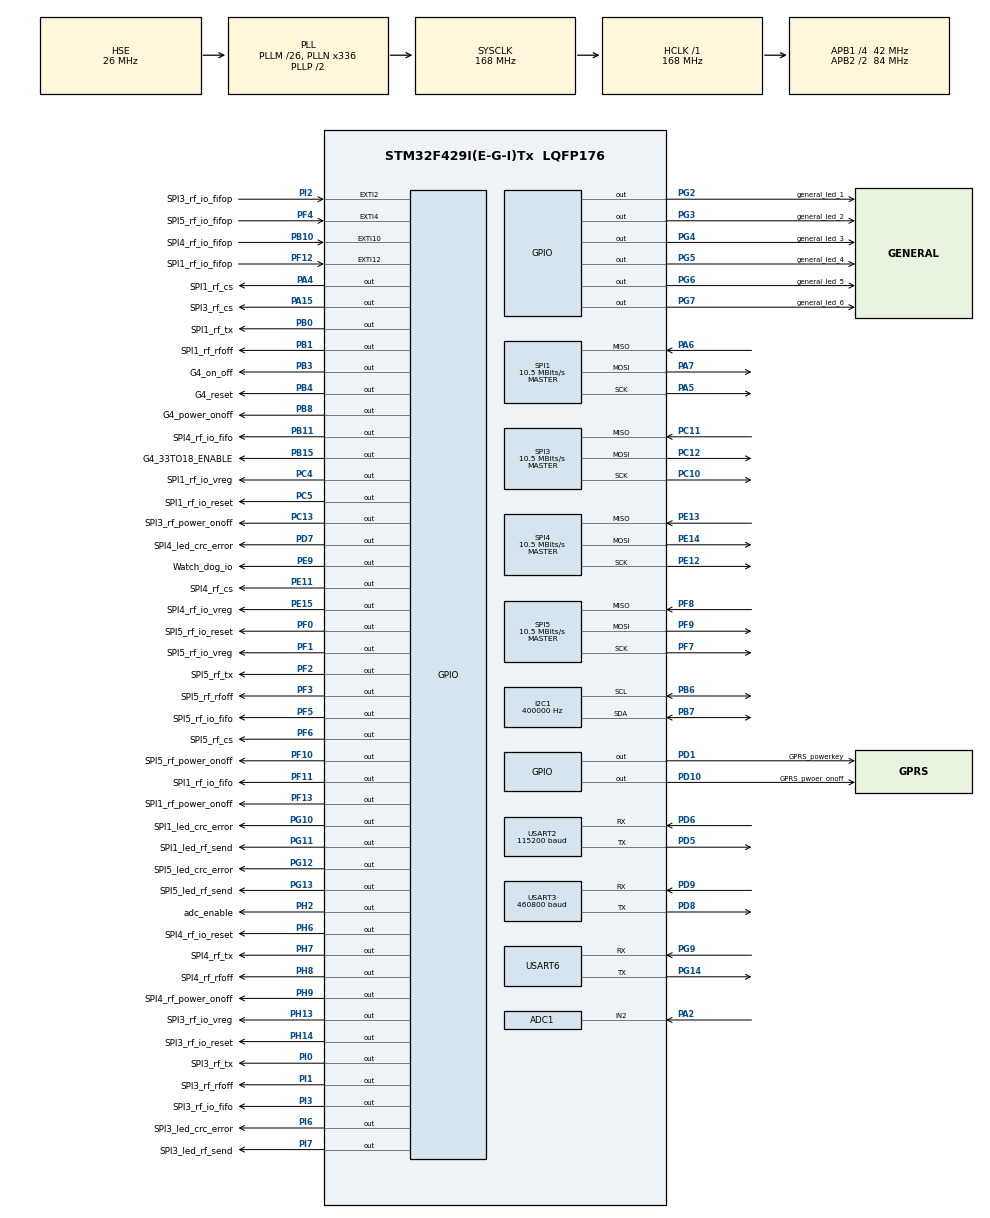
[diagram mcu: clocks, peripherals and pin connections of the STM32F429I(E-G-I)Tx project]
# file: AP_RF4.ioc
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ADC1.Channel-0\#ChannelRegularConversion=ADC_CHANNEL_2
ADC1.Channel-1\#ChannelRegularConversion=ADC_CHANNEL_2
ADC1.Channel-2\#ChannelRegularConversion=ADC_CHANNEL_2
ADC1.Channel-3\#ChannelRegularConversion=ADC_CHANNEL_2
ADC1.Channel-4\#ChannelRegularConversion=ADC_CHANNEL_2
ADC1.Channel-5\#ChannelRegularConversion=ADC_CHANNEL_2
ADC1.Channel-6\#ChannelRegularConversion=ADC_CHANNEL_2
ADC1.Channel-7\#ChannelRegularConversion=ADC_CHANNEL_2
ADC1.Channel-8\#ChannelRegularConversion=ADC_CHANNEL_2
ADC1.Channel-9\#ChannelRegularConversion=ADC_CHANNEL_2
ADC1.InjNumberOfConversion=0
ADC1.NbrOfConversion=10
ADC1.NbrOfConversionFlag=1
ADC1.Rank-0\#ChannelRegularConversion=1
ADC1.Rank-1\#ChannelRegularConversion=2
ADC1.Rank-2\#ChannelRegularConversion=3
ADC1.Rank-3\#ChannelRegularConversion=4
ADC1.Rank-4\#ChannelRegularConversion=5
ADC1.Rank-5\#ChannelRegularConversion=6
ADC1.Rank-6\#ChannelRegularConversion=7
ADC1.Rank-7\#ChannelRegularConversion=8
ADC1.Rank-8\#ChannelRegularConversion=9
ADC1.Rank-9\#ChannelRegularConversion=10
ADC1.SamplingTime-0\#ChannelRegularConversion=ADC_SAMPLETIME_3CYCLES
ADC1.SamplingTime-1\#ChannelRegularConversion=ADC_SAMPLETIME_3CYCLES
ADC1.SamplingTime-2\#ChannelRegularConversion=ADC_SAMPLETIME_3CYCLES
ADC1.SamplingTime-3\#ChannelRegularConversion=ADC_SAMPLETIME_3CYCLES
ADC1.SamplingTime-4\#ChannelRegularConversion=ADC_SAMPLETIME_3CYCLES
ADC1.SamplingTime-5\#ChannelRegularConversion=ADC_SAMPLETIME_3CYCLES
ADC1.SamplingTime-6\#ChannelRegularConversion=ADC_SAMPLETIME_3CYCLES
ADC1.SamplingTime-7\#ChannelRegularConversion=ADC_SAMPLETIME_3CYCLES
ADC1.SamplingTime-8\#ChannelRegularConversion=ADC_SAMPLETIME_3CYCLES
ADC1.SamplingTime-9\#ChannelRegularConversion=ADC_SAMPLETIME_3CYCLES
ADC1.ScanConvMode=ENABLE
ADC1.master=1
Dma.I2C1_RX.6.Direction=DMA_PERIPH_TO_MEMORY
Dma.I2C1_RX.6.FIFOMode=DMA_FIFOMODE_DISABLE
Dma.I2C1_RX.6.Instance=DMA1_Stream0
Dma.I2C1_RX.6.MemDataAlignment=DMA_MDATAALIGN_BYTE
Dma.I2C1_RX.6.MemInc=DMA_MINC_ENABLE
Dma.I2C1_RX.6.Mode=DMA_NORMAL
Dma.I2C1_RX.6.PeriphDataAlignment=DMA_PDATAALIGN_BYTE
Dma.I2C1_RX.6.PeriphInc=DMA_PINC_DISABLE
Dma.I2C1_RX.6.Priority=DMA_PRIORITY_VERY_HIGH
Dma.I2C1_TX.7.Direction=DMA_MEMORY_TO_PERIPH
Dma.I2C1_TX.7.FIFOMode=DMA_FIFOMODE_DISABLE
Dma.I2C1_TX.7.Instance=DMA1_Stream7
Dma.I2C1_TX.7.MemDataAlignment=DMA_MDATAALIGN_BYTE
Dma.I2C1_TX.7.MemInc=DMA_MINC_ENABLE
Dma.I2C1_TX.7.Mode=DMA_NORMAL
Dma.I2C1_TX.7.PeriphDataAlignment=DMA_PDATAALIGN_BYTE
Dma.I2C1_TX.7.PeriphInc=DMA_PINC_DISABLE
Dma.I2C1_TX.7.Priority=DMA_PRIORITY_VERY_HIGH
Dma.Request0=USART2_RX
Dma.Request1=USART2_TX
Dma.Request10=USART3_RX
Dma.Request11=USART3_TX
Dma.Request2=SPI1_RX
Dma.Request3=SPI5_RX
Dma.Request4=SPI4_RX
Dma.Request5=SPI3_RX
Dma.Request6=I2C1_RX
Dma.Request7=I2C1_TX
Dma.Request8=USART6_RX
Dma.Request9=USART6_TX
Dma.SPI1_RX.2.Direction=DMA_PERIPH_TO_MEMORY
Dma.SPI1_RX.2.FIFOMode=DMA_FIFOMODE_DISABLE
Dma.SPI1_RX.2.Instance=DMA2_Stream2
Dma.SPI1_RX.2.MemDataAlignment=DMA_MDATAALIGN_BYTE
Dma.SPI1_RX.2.MemInc=DMA_MINC_ENABLE
Dma.SPI1_RX.2.Mode=DMA_NORMAL
Dma.SPI1_RX.2.PeriphDataAlignment=DMA_PDATAALIGN_BYTE
Dma.SPI1_RX.2.PeriphInc=DMA_PINC_DISABLE
Dma.SPI1_RX.2.Priority=DMA_PRIORITY_MEDIUM
Dma.SPI3_RX.5.Direction=DMA_PERIPH_TO_MEMORY
Dma.SPI3_RX.5.FIFOMode=DMA_FIFOMODE_DISABLE
Dma.SPI3_RX.5.Instance=DMA1_Stream2
Dma.SPI3_RX.5.MemDataAlignment=DMA_MDATAALIGN_BYTE
Dma.SPI3_RX.5.MemInc=DMA_MINC_ENABLE
Dma.SPI3_RX.5.Mode=DMA_NORMAL
Dma.SPI3_RX.5.PeriphDataAlignment=DMA_PDATAALIGN_BYTE
Dma.SPI3_RX.5.PeriphInc=DMA_PINC_DISABLE
Dma.SPI3_RX.5.Priority=DMA_PRIORITY_MEDIUM
Dma.SPI4_RX.4.Direction=DMA_PERIPH_TO_MEMORY
Dma.SPI4_RX.4.FIFOMode=DMA_FIFOMODE_DISABLE
Dma.SPI4_RX.4.Instance=DMA2_Stream0
Dma.SPI4_RX.4.MemDataAlignment=DMA_MDATAALIGN_BYTE
Dma.SPI4_RX.4.MemInc=DMA_MINC_ENABLE
Dma.SPI4_RX.4.Mode=DMA_NORMAL
Dma.SPI4_RX.4.PeriphDataAlignment=DMA_PDATAALIGN_BYTE
Dma.SPI4_RX.4.PeriphInc=DMA_PINC_DISABLE
Dma.SPI4_RX.4.Priority=DMA_PRIORITY_MEDIUM
Dma.SPI5_RX.3.Direction=DMA_PERIPH_TO_MEMORY
Dma.SPI5_RX.3.FIFOMode=DMA_FIFOMODE_DISABLE
Dma.SPI5_RX.3.Instance=DMA2_Stream3
Dma.SPI5_RX.3.MemDataAlignment=DMA_MDATAALIGN_BYTE
Dma.SPI5_RX.3.MemInc=DMA_MINC_ENABLE
Dma.SPI5_RX.3.Mode=DMA_NORMAL
Dma.SPI5_RX.3.PeriphDataAlignment=DMA_PDATAALIGN_BYTE
Dma.SPI5_RX.3.PeriphInc=DMA_PINC_DISABLE
Dma.SPI5_RX.3.Priority=DMA_PRIORITY_MEDIUM
Dma.USART2_RX.0.Direction=DMA_PERIPH_TO_MEMORY
Dma.USART2_RX.0.FIFOMode=DMA_FIFOMODE_DISABLE
Dma.USART2_RX.0.Instance=DMA1_Stream5
Dma.USART2_RX.0.MemDataAlignment=DMA_MDATAALIGN_BYTE
Dma.USART2_RX.0.MemInc=DMA_MINC_ENABLE
Dma.USART2_RX.0.Mode=DMA_NORMAL
Dma.USART2_RX.0.PeriphDataAlignment=DMA_PDATAALIGN_BYTE
Dma.USART2_RX.0.PeriphInc=DMA_PINC_DISABLE
Dma.USART2_RX.0.Priority=DMA_PRIORITY_MEDIUM
Dma.USART2_TX.1.Direction=DMA_MEMORY_TO_PERIPH
Dma.USART2_TX.1.FIFOMode=DMA_FIFOMODE_DISABLE
Dma.USART2_TX.1.Instance=DMA1_Stream6
Dma.USART2_TX.1.MemDataAlignment=DMA_MDATAALIGN_BYTE
Dma.USART2_TX.1.MemInc=DMA_MINC_ENABLE
Dma.USART2_TX.1.Mode=DMA_NORMAL
Dma.USART2_TX.1.PeriphDataAlignment=DMA_PDATAALIGN_BYTE
Dma.USART2_TX.1.PeriphInc=DMA_PINC_DISABLE
Dma.USART2_TX.1.Priority=DMA_PRIORITY_MEDIUM
Dma.USART3_RX.10.Direction=DMA_PERIPH_TO_MEMORY
Dma.USART3_RX.10.FIFOMode=DMA_FIFOMODE_DISABLE
Dma.USART3_RX.10.Instance=DMA1_Stream1
Dma.USART3_RX.10.MemDataAlignment=DMA_MDATAALIGN_BYTE
Dma.USART3_RX.10.MemInc=DMA_MINC_ENABLE
Dma.USART3_RX.10.Mode=DMA_NORMAL
Dma.USART3_RX.10.PeriphDataAlignment=DMA_PDATAALIGN_BYTE
Dma.USART3_RX.10.PeriphInc=DMA_PINC_DISABLE
Dma.USART3_RX.10.Priority=DMA_PRIORITY_MEDIUM
Dma.USART3_TX.11.Direction=DMA_MEMORY_TO_PERIPH
Dma.USART3_TX.11.FIFOMode=DMA_FIFOMODE_DISABLE
Dma.USART3_TX.11.Instance=DMA1_Stream3
Dma.USART3_TX.11.MemDataAlignment=DMA_MDATAALIGN_BYTE
Dma.USART3_TX.11.MemInc=DMA_MINC_ENABLE
Dma.USART3_TX.11.Mode=DMA_NORMAL
Dma.USART3_TX.11.PeriphDataAlignment=DMA_PDATAALIGN_BYTE
Dma.USART3_TX.11.PeriphInc=DMA_PINC_DISABLE
Dma.USART3_TX.11.Priority=DMA_PRIORITY_MEDIUM
Dma.USART6_RX.8.Direction=DMA_PERIPH_TO_MEMORY
Dma.USART6_RX.8.FIFOMode=DMA_FIFOMODE_DISABLE
Dma.USART6_RX.8.Instance=DMA2_Stream1
Dma.USART6_RX.8.MemDataAlignment=DMA_MDATAALIGN_BYTE
Dma.USART6_RX.8.MemInc=DMA_MINC_ENABLE
Dma.USART6_RX.8.Mode=DMA_NORMAL
Dma.USART6_RX.8.PeriphDataAlignment=DMA_PDATAALIGN_BYTE
Dma.USART6_RX.8.PeriphInc=DMA_PINC_DISABLE
Dma.USART6_RX.8.Priority=DMA_PRIORITY_MEDIUM
Dma.USART6_TX.9.Direction=DMA_MEMORY_TO_PERIPH
Dma.USART6_TX.9.FIFOMode=DMA_FIFOMODE_DISABLE
Dma.USART6_TX.9.Instance=DMA2_Stream6
Dma.USART6_TX.9.MemDataAlignment=DMA_MDATAALIGN_BYTE
Dma.USART6_TX.9.MemInc=DMA_MINC_ENABLE
Dma.USART6_TX.9.Mode=DMA_NORMAL
Dma.USART6_TX.9.PeriphDataAlignment=DMA_PDATAALIGN_BYTE
Dma.USART6_TX.9.PeriphInc=DMA_PINC_DISABLE
Dma.USART6_TX.9.Priority=DMA_PRIORITY_MEDIUM
I2C1.ClockSpeed=400000
I2C1.I2C_Mode=I2C_Fast
Mcu.Family=STM32F4
Mcu.Name=STM32F429I(E-G-I)Tx
Mcu.Package=LQFP176
NVIC.ADC_IRQn=true\:0\:0\:false\:false\:true
NVIC.DMA1_Stream0_IRQn=true\:0\:0\:true\:false\:true
NVIC.DMA1_Stream1_IRQn=true\:2\:0\:true\:false\:true
NVIC.DMA1_Stream2_IRQn=true\:1\:0\:false\:false\:true
NVIC.DMA1_Stream3_IRQn=true\:2\:0\:true\:false\:true
NVIC.DMA1_Stream5_IRQn=true\:2\:0\:true\:false\:true
NVIC.DMA1_Stream6_IRQn=true\:2\:0\:true\:false\:true
NVIC.DMA1_Stream7_IRQn=true\:0\:0\:false\:false\:true
NVIC.DMA2_Stream0_IRQn=true\:1\:0\:true\:false\:true
NVIC.DMA2_Stream1_IRQn=true\:2\:0\:true\:false\:true
NVIC.DMA2_Stream2_IRQn=true\:1\:0\:true\:false\:true
NVIC.DMA2_Stream3_IRQn=true\:1\:0\:false\:false\:true
NVIC.DMA2_Stream6_IRQn=true\:2\:0\:false\:false\:true
NVIC.EXTI15_10_IRQn=true\:1\:0\:true\:false\:true
NVIC.EXTI2_IRQn=true\:2\:0\:true\:false\:true
NVIC.EXTI4_IRQn=true\:2\:0\:true\:false\:true
NVIC.I2C1_ER_IRQn=true\:0\:0\:false\:false\:true
NVIC.I2C1_EV_IRQn=true\:0\:0\:false\:false\:true
NVIC.PriorityGroup=NVIC_PRIORITYGROUP_4
NVIC.USART2_IRQn=true\:1\:0\:true\:false\:true
NVIC.USART3_IRQn=true\:1\:0\:true\:false\:true
NVIC.USART6_IRQn=true\:1\:0\:true\:false\:true
PA13.Mode=Serial_Wire
PA13.Signal=SYS_JTMS-SWDIO
PA14.Mode=Serial_Wire
PA14.Signal=SYS_JTCK-SWCLK
PA15.GPIO_Label=SPI3_rf_cs
PA15.GPIO_PuPd=GPIO_PULLUP
PA15.GPIO_Speed=GPIO_SPEED_FREQ_VERY_HIGH
PA15.PinState=GPIO_PIN_SET
PA15.Signal=GPIO_Output
PA2.Signal=ADCx_IN2
PA4.GPIO_Label=SPI1_rf_cs
PA4.GPIO_ModeDefaultOutputPP=GPIO_MODE_OUTPUT_PP
PA4.GPIO_PuPd=GPIO_PULLUP
PA4.GPIO_Speed=GPIO_SPEED_FREQ_VERY_HIGH
PA4.PinState=GPIO_PIN_SET
PA4.Signal=GPIO_Output
PA5.Mode=Full_Duplex_Master
PA5.Signal=SPI1_SCK
PA6.Mode=Full_Duplex_Master
PA6.Signal=SPI1_MISO
PA7.Mode=Full_Duplex_Master
PA7.Signal=SPI1_MOSI
PB0.GPIO_Label=SPI1_rf_tx
PB0.GPIO_PuPd=GPIO_PULLUP
PB0.GPIO_Speed=GPIO_SPEED_FREQ_VERY_HIGH
PB0.PinState=GPIO_PIN_SET
PB0.Signal=GPIO_Output
PB1.GPIO_Label=SPI1_rf_rfoff
PB1.GPIO_ModeDefaultOutputPP=GPIO_MODE_OUTPUT_PP
PB1.GPIO_PuPd=GPIO_PULLUP
PB1.GPIO_Speed=GPIO_SPEED_FREQ_VERY_HIGH
PB1.PinState=GPIO_PIN_SET
PB1.Signal=GPIO_Output
PB10.GPIO_Label=SPI4_rf_io_fifop
PB10.GPIO_ModeDefaultEXTI=GPIO_MODE_IT_RISING
PB10.GPIO_PuPd=GPIO_NOPULL
PB10.Signal=GPXTI10
PB11.GPIO_Label=SPI4_rf_io_fifo
PB11.GPIO_ModeDefaultOutputPP=GPIO_MODE_OUTPUT_PP
PB11.GPIO_PuPd=GPIO_PULLUP
PB11.GPIO_Speed=GPIO_SPEED_FREQ_VERY_HIGH
PB11.PinState=GPIO_PIN_SET
PB11.Signal=GPIO_Output
PB15.GPIO_Label=G4_33TO18_ENABLE
PB15.GPIO_ModeDefaultOutputPP=GPIO_MODE_OUTPUT_OD
PB15.GPIO_PuPd=GPIO_PULLUP
PB15.GPIO_Speed=GPIO_SPEED_FREQ_HIGH
PB15.PinState=GPIO_PIN_SET
PB15.Signal=GPIO_Output
PB3.GPIO_Label=G4_on_off
PB3.GPIO_ModeDefaultOutputPP=GPIO_MODE_OUTPUT_PP
PB3.GPIO_PuPd=GPIO_PULLUP
PB3.GPIO_Speed=GPIO_SPEED_FREQ_MEDIUM
PB3.PinState=GPIO_PIN_SET
PB3.Signal=GPIO_Output
PB4.GPIO_Label=G4_reset
PB4.GPIO_ModeDefaultOutputPP=GPIO_MODE_OUTPUT_PP
PB4.GPIO_PuPd=GPIO_PULLUP
PB4.GPIO_Speed=GPIO_SPEED_FREQ_HIGH
PB4.PinState=GPIO_PIN_SET
PB4.Signal=GPIO_Output
PB6.GPIO_PuPdOD=GPIO_NOPULL
PB6.Mode=I2C
PB6.Signal=I2C1_SCL
PB7.GPIO_PuPdOD=GPIO_NOPULL
PB7.Mode=I2C
PB7.Signal=I2C1_SDA
PB8.GPIO_Label=G4_power_onoff
PB8.GPIO_PuPd=GPIO_PULLUP
PB8.GPIO_Speed=GPIO_SPEED_FREQ_MEDIUM
PB8.PinState=GPIO_PIN_SET
PB8.Signal=GPIO_Output
PC10.Mode=Full_Duplex_Master
PC10.Signal=SPI3_SCK
PC11.Mode=Full_Duplex_Master
PC11.Signal=SPI3_MISO
PC12.Mode=Full_Duplex_Master
PC12.Signal=SPI3_MOSI
PC13.GPIO_Label=SPI3_rf_power_onoff
PC13.GPIO_ModeDefaultOutputPP=GPIO_MODE_OUTPUT_PP
PC13.GPIO_PuPd=GPIO_PULLUP
PC13.Signal=GPIO_Output
PC14/OSC32_IN.Mode=LSE-External-Oscillator
PC14/OSC32_IN.Signal=RCC_OSC32_IN
PC15/OSC32_OUT.Mode=LSE-External-Oscillator
PC15/OSC32_OUT.Signal=RCC_OSC32_OUT
PC4.GPIO_Label=SPI1_rf_io_vreg
PC4.GPIO_ModeDefaultOutputPP=GPIO_MODE_OUTPUT_PP
PC4.GPIO_PuPd=GPIO_PULLUP
PC4.GPIO_Speed=GPIO_SPEED_FREQ_VERY_HIGH
PC4.PinState=GPIO_PIN_SET
PC4.Signal=GPIO_Output
PC5.GPIO_Label=SPI1_rf_io_reset
PC5.GPIO_ModeDefaultOutputPP=GPIO_MODE_OUTPUT_PP
PC5.GPIO_PuPd=GPIO_PULLUP
PC5.GPIO_Speed=GPIO_SPEED_FREQ_VERY_HIGH
PC5.PinState=GPIO_PIN_SET
PC5.Signal=GPIO_Output
PD1.GPIO_Label=GPRS_powerkey
PD1.GPIO_PuPd=GPIO_PULLDOWN
PD1.PinState=GPIO_PIN_SET
PD1.Signal=GPIO_Output
PD10.GPIO_Label=GPRS_pwoer_onoff
PD10.GPIO_ModeDefaultOutputPP=GPIO_MODE_OUTPUT_PP
PD10.GPIO_PuPd=GPIO_PULLUP
PD10.PinState=GPIO_PIN_RESET
PD10.Signal=GPIO_Output
PD5.Mode=Asynchronous
PD5.Signal=USART2_TX
PD6.Mode=Asynchronous
PD6.Signal=USART2_RX
PD7.GPIO_Label=SPI4_led_crc_error
PD7.GPIO_ModeDefaultOutputPP=GPIO_MODE_OUTPUT_OD
PD7.GPIO_PuPd=GPIO_PULLUP
PD7.Signal=GPIO_Output
PD8.Mode=Asynchronous
PD8.Signal=USART3_TX
PD9.Mode=Asynchronous
PD9.Signal=USART3_RX
PE11.GPIO_Label=SPI4_rf_cs
PE11.GPIO_PuPd=GPIO_PULLUP
PE11.GPIO_Speed=GPIO_SPEED_FREQ_VERY_HIGH
PE11.PinState=GPIO_PIN_SET
PE11.Signal=GPIO_Output
PE12.Mode=Full_Duplex_Master
PE12.Signal=SPI4_SCK
PE13.Mode=Full_Duplex_Master
PE13.Signal=SPI4_MISO
PE14.Mode=Full_Duplex_Master
PE14.Signal=SPI4_MOSI
PE15.GPIO_Label=SPI4_rf_io_vreg
PE15.GPIO_PuPd=GPIO_PULLUP
PE15.Signal=GPIO_Output
PE9.GPIO_Label=Watch_dog_io
PE9.GPIO_ModeDefaultOutputPP=GPIO_MODE_OUTPUT_PP
PE9.GPIO_PuPd=GPIO_PULLUP
PE9.GPIO_Speed=GPIO_SPEED_FREQ_VERY_HIGH
PE9.PinState=GPIO_PIN_SET
PE9.Signal=GPIO_Output
PF0.GPIO_Label=SPI5_rf_io_reset
PF0.GPIO_ModeDefaultOutputPP=GPIO_MODE_OUTPUT_PP
PF0.GPIO_PuPd=GPIO_PULLUP
PF0.GPIO_Speed=GPIO_SPEED_FREQ_VERY_HIGH
PF0.PinState=GPIO_PIN_SET
PF0.Signal=GPIO_Output
PF1.GPIO_Label=SPI5_rf_io_vreg
PF1.GPIO_PuPd=GPIO_PULLUP
PF1.GPIO_Speed=GPIO_SPEED_FREQ_VERY_HIGH
PF1.PinState=GPIO_PIN_SET
PF1.Signal=GPIO_Output
PF10.GPIO_Label=SPI5_rf_power_onoff
PF10.GPIO_ModeDefaultOutputPP=GPIO_MODE_OUTPUT_PP
PF10.GPIO_PuPd=GPIO_PULLUP
PF10.Signal=GPIO_Output
PF11.GPIO_Label=SPI1_rf_io_fifo
PF11.GPIO_ModeDefaultOutputPP=GPIO_MODE_OUTPUT_PP
PF11.GPIO_PuPd=GPIO_PULLUP
PF11.GPIO_Speed=GPIO_SPEED_FREQ_VERY_HIGH
PF11.PinState=GPIO_PIN_SET
PF11.Signal=GPIO_Output
PF12.GPIO_Label=SPI1_rf_io_fifop
PF12.Signal=GPXTI12
PF13.GPIO_Label=SPI1_rf_power_onoff
PF13.GPIO_ModeDefaultOutputPP=GPIO_MODE_OUTPUT_PP
PF13.GPIO_PuPd=GPIO_PULLUP
PF13.Signal=GPIO_Output
PF2.GPIO_Label=SPI5_rf_tx
PF2.GPIO_PuPd=GPIO_PULLUP
PF2.GPIO_Speed=GPIO_SPEED_FREQ_VERY_HIGH
PF2.PinState=GPIO_PIN_SET
PF2.Signal=GPIO_Output
PF3.GPIO_Label=SPI5_rf_rfoff
PF3.GPIO_PuPd=GPIO_PULLUP
PF3.GPIO_Speed=GPIO_SPEED_FREQ_VERY_HIGH
PF3.PinState=GPIO_PIN_SET
PF3.Signal=GPIO_Output
PF4.GPIO_Label=SPI5_rf_io_fifop
PF4.GPIO_ModeDefaultEXTI=GPIO_MODE_IT_RISING
PF4.GPIO_PuPd=GPIO_NOPULL
PF4.Signal=GPXTI4
PF5.GPIO_Label=SPI5_rf_io_fifo
PF5.GPIO_ModeDefaultOutputPP=GPIO_MODE_OUTPUT_PP
PF5.GPIO_PuPd=GPIO_PULLUP
PF5.GPIO_Speed=GPIO_SPEED_FREQ_VERY_HIGH
PF5.PinState=GPIO_PIN_SET
PF5.Signal=GPIO_Output
PF6.GPIO_Label=SPI5_rf_cs
PF6.GPIO_ModeDefaultOutputPP=GPIO_MODE_OUTPUT_PP
PF6.GPIO_PuPd=GPIO_PULLUP
PF6.GPIO_Speed=GPIO_SPEED_FREQ_VERY_HIGH
PF6.PinState=GPIO_PIN_SET
PF6.Signal=GPIO_Output
PF7.Mode=Full_Duplex_Master
PF7.Signal=SPI5_SCK
PF8.Mode=Full_Duplex_Master
PF8.Signal=SPI5_MISO
PF9.Mode=Full_Duplex_Master
PF9.Signal=SPI5_MOSI
PG10.GPIO_Label=SPI1_led_crc_error
PG10.GPIO_ModeDefaultOutputPP=GPIO_MODE_OUTPUT_OD
PG10.GPIO_PuPd=GPIO_PULLUP
PG10.Signal=GPIO_Output
PG11.GPIO_Label=SPI1_led_rf_send
PG11.GPIO_ModeDefaultOutputPP=GPIO_MODE_OUTPUT_OD
PG11.GPIO_PuPd=GPIO_PULLUP
PG11.Signal=GPIO_Output
PG12.GPIO_Label=SPI5_led_crc_error
PG12.GPIO_ModeDefaultOutputPP=GPIO_MODE_OUTPUT_OD
PG12.GPIO_PuPd=GPIO_PULLUP
PG12.Signal=GPIO_Output
PG13.GPIO_Label=SPI5_led_rf_send
PG13.GPIO_ModeDefaultOutputPP=GPIO_MODE_OUTPUT_OD
PG13.GPIO_PuPd=GPIO_PULLUP
PG13.Signal=GPIO_Output
PG14.Mode=Asynchronous
PG14.Signal=USART6_TX
PG2.GPIO_Label=general_led_1
PG2.GPIO_ModeDefaultOutputPP=GPIO_MODE_OUTPUT_OD
PG2.GPIO_PuPd=GPIO_PULLUP
PG2.GPIO_Speed=GPIO_SPEED_FREQ_LOW
PG2.PinState=GPIO_PIN_RESET
PG2.Signal=GPIO_Output
PG3.GPIO_Label=general_led_2
PG3.GPIO_ModeDefaultOutputPP=GPIO_MODE_OUTPUT_OD
PG3.GPIO_PuPd=GPIO_PULLUP
PG3.GPIO_Speed=GPIO_SPEED_FREQ_LOW
PG3.PinState=GPIO_PIN_RESET
PG3.Signal=GPIO_Output
PG4.GPIO_Label=general_led_3
PG4.GPIO_ModeDefaultOutputPP=GPIO_MODE_OUTPUT_OD
PG4.GPIO_PuPd=GPIO_PULLUP
PG4.GPIO_Speed=GPIO_SPEED_FREQ_LOW
PG4.PinState=GPIO_PIN_RESET
PG4.Signal=GPIO_Output
PG5.GPIO_Label=general_led_4
PG5.GPIO_ModeDefaultOutputPP=GPIO_MODE_OUTPUT_OD
PG5.GPIO_PuPd=GPIO_PULLUP
PG5.GPIO_Speed=GPIO_SPEED_FREQ_LOW
PG5.PinState=GPIO_PIN_RESET
PG5.Signal=GPIO_Output
PG6.GPIO_Label=general_led_5
PG6.GPIO_ModeDefaultOutputPP=GPIO_MODE_OUTPUT_OD
PG6.GPIO_PuPd=GPIO_PULLUP
PG6.GPIO_Speed=GPIO_SPEED_FREQ_LOW
PG6.PinState=GPIO_PIN_RESET
PG6.Signal=GPIO_Output
PG7.GPIO_Label=general_led_6
PG7.GPIO_ModeDefaultOutputPP=GPIO_MODE_OUTPUT_OD
PG7.GPIO_PuPd=GPIO_PULLUP
PG7.GPIO_Speed=GPIO_SPEED_FREQ_LOW
PG7.PinState=GPIO_PIN_SET
PG7.Signal=GPIO_Output
PG9.Mode=Asynchronous
PG9.Signal=USART6_RX
PH0/OSC_IN.Mode=HSE-External-Clock-Source
PH0/OSC_IN.Signal=RCC_OSC_IN
PH1/OSC_OUT.Mode=HSE-External-Clock-Source
PH1/OSC_OUT.Signal=RCC_OSC_OUT
PH13.GPIO_Label=SPI3_rf_io_vreg
PH13.GPIO_PuPd=GPIO_PULLUP
PH13.Signal=GPIO_Output
PH14.GPIO_Label=SPI3_rf_io_reset
PH14.GPIO_ModeDefaultOutputPP=GPIO_MODE_OUTPUT_PP
PH14.GPIO_PuPd=GPIO_PULLUP
PH14.GPIO_Speed=GPIO_SPEED_FREQ_MEDIUM
PH14.PinState=GPIO_PIN_SET
PH14.Signal=GPIO_Output
PH2.GPIO_Label=adc_enable
PH2.GPIO_ModeDefaultOutputPP=GPIO_MODE_OUTPUT_PP
PH2.GPIO_PuPd=GPIO_NOPULL
PH2.GPIO_Speed=GPIO_SPEED_FREQ_HIGH
PH2.PinState=GPIO_PIN_SET
PH2.Signal=GPIO_Output
PH6.GPIO_Label=SPI4_rf_io_reset
PH6.GPIO_ModeDefaultOutputPP=GPIO_MODE_OUTPUT_PP
PH6.GPIO_PuPd=GPIO_PULLUP
PH6.Signal=GPIO_Output
PH7.GPIO_Label=SPI4_rf_tx
PH7.GPIO_PuPd=GPIO_PULLUP
PH7.GPIO_Speed=GPIO_SPEED_FREQ_VERY_HIGH
PH7.PinState=GPIO_PIN_SET
PH7.Signal=GPIO_Output
PH8.GPIO_Label=SPI4_rf_rfoff
PH8.GPIO_PuPd=GPIO_PULLUP
PH8.GPIO_Speed=GPIO_SPEED_FREQ_VERY_HIGH
PH8.PinState=GPIO_PIN_SET
PH8.Signal=GPIO_Output
PH9.GPIO_Label=SPI4_rf_power_onoff
PH9.GPIO_PuPd=GPIO_PULLUP
PH9.Signal=GPIO_Output
PI0.GPIO_Label=SPI3_rf_tx
PI0.GPIO_PuPd=GPIO_PULLUP
PI0.GPIO_Speed=GPIO_SPEED_FREQ_VERY_HIGH
PI0.PinState=GPIO_PIN_SET
PI0.Signal=GPIO_Output
PI1.GPIO_Label=SPI3_rf_rfoff
PI1.GPIO_PuPd=GPIO_PULLUP
PI1.GPIO_Speed=GPIO_SPEED_FREQ_VERY_HIGH
PI1.PinState=GPIO_PIN_SET
PI1.Signal=GPIO_Output
PI2.GPIO_Label=SPI3_rf_io_fifop
PI2.Signal=GPXTI2
PI3.GPIO_Label=SPI3_rf_io_fifo
PI3.GPIO_ModeDefaultOutputPP=GPIO_MODE_OUTPUT_PP
PI3.GPIO_PuPd=GPIO_PULLUP
PI3.GPIO_Speed=GPIO_SPEED_FREQ_VERY_HIGH
PI3.PinState=GPIO_PIN_SET
PI3.Signal=GPIO_Output
PI6.GPIO_Label=SPI3_led_crc_error
PI6.GPIO_ModeDefaultOutputPP=GPIO_MODE_OUTPUT_OD
PI6.GPIO_PuPd=GPIO_PULLUP
PI6.Signal=GPIO_Output
PI7.GPIO_Label=SPI3_led_rf_send
PI7.GPIO_ModeDefaultOutputPP=GPIO_MODE_OUTPUT_OD
PI7.GPIO_PuPd=GPIO_PULLUP
PI7.Signal=GPIO_Output
ProjectManager.HeapSize=0x200
ProjectManager.StackSize=0x800
ProjectManager.TargetToolchain=MDK-ARM V5
RCC.48MHZClocksFreq_Value=84000000
RCC.AHBFreq_Value=168000000
RCC.APB1CLKDivider=RCC_HCLK_DIV4
RCC.APB1Freq_Value=42000000
RCC.APB1TimFreq_Value=84000000
RCC.APB2CLKDivider=RCC_HCLK_DIV2
RCC.APB2Freq_Value=84000000
RCC.APB2TimFreq_Value=168000000
RCC.CortexFreq_Value=168000000
RCC.HCLKFreq_Value=168000000
RCC.HSE_VALUE=26000000
RCC.HSI_VALUE=16000000
RCC.PLLM=26
RCC.PLLN=336
RCC.PLLSourceVirtual=RCC_PLLSOURCE_HSE
RCC.RCC_RTC_Clock_SourceVirtual=RCC_RTCCLKSOURCE_LSE
RCC.SYSCLKFreq_VALUE=168000000
RCC.SYSCLKSource=RCC_SYSCLKSOURCE_PLLCLK
RCC.VCOOutputFreq_Value=336000000
RTC.Format=RTC_FORMAT_BIN
SH.ADCx_IN2.0=ADC1_IN2,IN2
SPI1.BaudRatePrescaler=SPI_BAUDRATEPRESCALER_8
SPI1.CLKPhase=SPI_PHASE_1EDGE
SPI1.CalculateBaudRate=10.5 MBits/s
SPI1.Direction=SPI_DIRECTION_2LINES
SPI1.Mode=SPI_MODE_MASTER
SPI1.VirtualType=VM_MASTER
SPI3.BaudRatePrescaler=SPI_BAUDRATEPRESCALER_4
SPI3.CalculateBaudRate=10.5 MBits/s
SPI3.Direction=SPI_DIRECTION_2LINES
SPI3.Mode=SPI_MODE_MASTER
SPI3.TIMode=SPI_TIMODE_DISABLE
SPI3.VirtualType=VM_MASTER
SPI4.BaudRatePrescaler=SPI_BAUDRATEPRESCALER_8
SPI4.CalculateBaudRate=10.5 MBits/s
SPI4.Direction=SPI_DIRECTION_2LINES
SPI4.Mode=SPI_MODE_MASTER
SPI4.VirtualType=VM_MASTER
SPI5.BaudRatePrescaler=SPI_BAUDRATEPRESCALER_8
SPI5.CalculateBaudRate=10.5 MBits/s
SPI5.Direction=SPI_DIRECTION_2LINES
SPI5.Mode=SPI_MODE_MASTER
SPI5.VirtualType=VM_MASTER
TIM2.ClockDivision=TIM_CLOCKDIVISION_DIV1
TIM2.Period=800000
TIM2.Prescaler=168
USART2.BaudRate=115200
USART2.VirtualMode=VM_ASYNC
USART3.BaudRate=460800
USART3.VirtualMode=VM_ASYNC
USART6.VirtualMode=VM_ASYNC
VP_CRC_VS_CRC.Mode=CRC_Activate
VP_RTC_VS_RTC_Activate.Mode=RTC_Enabled
VP_RTC_VS_RTC_Calendar.Mode=RTC_Calendar
VP_TIM2_VS_ClockSourceINT.Mode=Internal
board=AP_RF4

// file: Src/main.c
/**
  ******************************************************************************
  * File Name          : main.c
  * Description        : Main program body
  ******************************************************************************
  ** This notice applies to any and all portions of this file
  * that are not between comment pairs USER CODE BEGIN and
  * USER CODE END. Other portions of this file, whether
  * inserted by the user or by software development tools
  * are owned by their respective copyright owners.
  *
  * COPYRIGHT(c) 2019 STMicroelectronics
  *
  * Redistribution and use in source and binary forms, with or without modification,
  * are permitted provided that the following conditions are met:
  *   1. Redistributions of source code must retain the above copyright notice,
  *      this list of conditions and the following disclaimer.
  *   2. Redistributions in binary form must reproduce the above copyright notice,
  *      this list of conditions and the following disclaimer in the documentation
  *      and/or other materials provided with the distribution.
  *   3. Neither the name of STMicroelectronics nor the names of its contributors
  *      may be used to endorse or promote products derived from this software
  *      without specific prior written permission.
  *
  * THIS SOFTWARE IS PROVIDED BY THE COPYRIGHT HOLDERS AND CONTRIBUTORS "AS IS"
  * AND ANY EXPRESS OR IMPLIED WARRANTIES, INCLUDING, BUT NOT LIMITED TO, THE
  * IMPLIED WARRANTIES OF MERCHANTABILITY AND FITNESS FOR A PARTICULAR PURPOSE ARE
  * DISCLAIMED. IN NO EVENT SHALL THE COPYRIGHT HOLDER OR CONTRIBUTORS BE LIABLE
  * FOR ANY DIRECT, INDIRECT, INCIDENTAL, SPECIAL, EXEMPLARY, OR CONSEQUENTIAL
  * DAMAGES (INCLUDING, BUT NOT LIMITED TO, PROCUREMENT OF SUBSTITUTE GOODS OR
  * SERVICES; LOSS OF USE, DATA, OR PROFITS; OR BUSINESS INTERRUPTION) HOWEVER
  * CAUSED AND ON ANY THEORY OF LIABILITY, WHETHER IN CONTRACT, STRICT LIABILITY,
  * OR TORT (INCLUDING NEGLIGENCE OR OTHERWISE) ARISING IN ANY WAY OUT OF THE USE
  * OF THIS SOFTWARE, EVEN IF ADVISED OF THE POSSIBILITY OF SUCH DAMAGE.
  *
  ******************************************************************************
  */
#include "main.h"
#include "stm32f4xx_hal.h"

/* USER CODE BEGIN Includes */

#include "typedef_struct.h"
#include "ap_param.h"
#include "eeprom.h"
#include "flash.h"
#include "rf_hal.h"
#include "debug_uart.h"
#include "rf_data_handle.h"
#include "gprs_4g_app.h"

extern void to_n1_buff_handle();
extern void start_from_n1_dma_receive();
extern void start_from_gprs_dma_receive();
extern void start_from_debug_dma_receive();
extern void gprs_main_call();
extern void rf_power_off(SPI_HandleTypeDef* hspi);
extern void rf_power_on(SPI_HandleTypeDef* hspi);
extern void led_1_close();
extern int rf_init(SPI_HandleTypeDef* hspi);
extern void rf_manage();
extern void debug_cmd_handle(void);
extern int rf_io_tx(SPI_HandleTypeDef* hspi);
extern void rf_cmd_tx(SPI_HandleTypeDef* hspi);
extern void rf_write_buff(SPI_HandleTypeDef* hspi,void *ptr,int len);
extern HAL_StatusTypeDef ee_read(uint32_t ee_address,uint16_t size);
extern HAL_StatusTypeDef ee_write(uint32_t ee_address,uint16_t size);
extern HAL_StatusTypeDef ee_write_no(uint32_t ee_address,uint16_t size);
extern HAL_StatusTypeDef ee_read_no(uint32_t ee_address,uint16_t size);
extern void read_ap_param(void);
extern void ee_task_poll(void);
extern void read_firmware_rp_head();
extern void read_firmware_sensor_head();
extern void make_result_test_1000p();

extern struct_systerm_info systerm_info;
extern uint8_t ap_param_write_flash_flag;
extern struct_rf_stat rf_stat[4];

/* USER CODE END Includes */

ADC_HandleTypeDef hadc1;

CRC_HandleTypeDef hcrc;

I2C_HandleTypeDef hi2c1;
DMA_HandleTypeDef hdma_i2c1_rx;
DMA_HandleTypeDef hdma_i2c1_tx;

RTC_HandleTypeDef hrtc;

SPI_HandleTypeDef hspi1;
SPI_HandleTypeDef hspi3;
SPI_HandleTypeDef hspi4;
SPI_HandleTypeDef hspi5;
DMA_HandleTypeDef hdma_spi1_rx;
DMA_HandleTypeDef hdma_spi3_rx;
DMA_HandleTypeDef hdma_spi4_rx;
DMA_HandleTypeDef hdma_spi5_rx;

TIM_HandleTypeDef htim2;

UART_HandleTypeDef huart2;
UART_HandleTypeDef huart3;
UART_HandleTypeDef huart6;
DMA_HandleTypeDef hdma_usart2_rx;
DMA_HandleTypeDef hdma_usart2_tx;
DMA_HandleTypeDef hdma_usart3_rx;
DMA_HandleTypeDef hdma_usart3_tx;
DMA_HandleTypeDef hdma_usart6_rx;
DMA_HandleTypeDef hdma_usart6_tx;

/* USER CODE BEGIN PV */
/* Private variables ---------------------------------------------------------*/
int core_freq = 0;
uint8_t data[24] = {10,1,2,3,4,5,6,7,8,9,10,11,12};
/* USER CODE END PV */

void SystemClock_Config(void);
static void MX_GPIO_Init(void);
static void MX_DMA_Init(void);
static void MX_SPI5_Init(void);
static void MX_USART2_UART_Init(void);
static void MX_USART3_UART_Init(void);
static void MX_SPI1_Init(void);
static void MX_SPI4_Init(void);
static void MX_SPI3_Init(void);
static void MX_USART6_UART_Init(void);
static void MX_I2C1_Init(void);
static void MX_CRC_Init(void);
static void MX_TIM2_Init(void);
static void MX_RTC_Init(void);
static void MX_ADC1_Init(void);

/* USER CODE BEGIN PFP */
/* Private function prototypes -----------------------------------------------*/

/* USER CODE END PFP */

/* USER CODE BEGIN 0 */
HAL_StatusTypeDef iic_stat;
FLASH_EraseInitTypeDef EraseInit;
uint32_t SectorError	;
int32_t adc_getvalue_enable;

void user_sys_init(void)
{
	init_ap_param();
	read_ap_param_flash();
	rf_satt_init();

	HAL_SYSTICK_CLKSourceConfig(SYSTICK_CLKSOURCE_HCLK);      //启动systick 2ms中断
	HAL_SYSTICK_Config(328125);
	HAL_NVIC_SetPriority(SysTick_IRQn, 0, 0);

	core_freq = HAL_RCC_GetSysClockFreq();

	start_from_n1_dma_receive();
	start_from_gprs_dma_receive();
	start_from_debug_dma_receive();

	led_1_close();
	HAL_TIM_Base_Start(&htim2);

	systerm_info.enable_rf = 1;   //使能2ms中断中rf发送包

	read_firmware_rp_head();
	read_firmware_sensor_head();

	print_version();
}

/* USER CODE END 0 */

int main(void)
{

  /* USER CODE BEGIN 1 */
	int32_t delay = 0;
  /* USER CODE END 1 */

  /* MCU Configuration----------------------------------------------------------*/

  /* Reset of all peripherals, Initializes the Flash interface and the Systick. */
  HAL_Init();

  /* Configure the system clock */
  SystemClock_Config();

  /* Initialize all configured peripherals */
  MX_GPIO_Init();
  MX_DMA_Init();
  MX_SPI5_Init();
  MX_USART2_UART_Init();
  MX_USART3_UART_Init();
  MX_SPI1_Init();
  MX_SPI4_Init();
  MX_SPI3_Init();
  MX_USART6_UART_Init();
  MX_I2C1_Init();
  MX_CRC_Init();
  MX_TIM2_Init();
  MX_RTC_Init();
  MX_ADC1_Init();

  /* USER CODE BEGIN 2 */
	user_sys_init();

  /* USER CODE END 2 */

  /* Infinite loop */
  while (1)
  {

  /* USER CODE BEGIN 3 */
		HAL_GPIO_TogglePin(Watch_dog_io_GPIO_Port,Watch_dog_io_Pin);

		rf_manage();
		debug_cmd_handle();
		to_n1_buff_handle();
		gprs_main_call();

		if(ap_param_write_flash_flag)
		{
			write_ap_param_flash();
		}
		if(adc_getvalue_enable)
		{
			adc_getvalue_enable = 0;
			HAL_ADC_Start_IT(&hadc1);
		}
		make_result_test_1000p();
		debug_send_double_buff_poll();
		gprs_4g_task_poll();
		sensor_event_and_stat_hanle();
  }
  /* USER CODE END 3 */

}

/** System Clock Configuration
*/
void SystemClock_Config(void)
{

  RCC_OscInitTypeDef RCC_OscInitStruct;
  RCC_ClkInitTypeDef RCC_ClkInitStruct;
  RCC_PeriphCLKInitTypeDef PeriphClkInitStruct;

    /**Configure the main internal regulator output voltage
    */
  __HAL_RCC_PWR_CLK_ENABLE();

  __HAL_PWR_VOLTAGESCALING_CONFIG(PWR_REGULATOR_VOLTAGE_SCALE1);

    /**Initializes the CPU, AHB and APB busses clocks
    */
  RCC_OscInitStruct.OscillatorType = RCC_OSCILLATORTYPE_HSE|RCC_OSCILLATORTYPE_LSE;
  RCC_OscInitStruct.HSEState = RCC_HSE_BYPASS;
  RCC_OscInitStruct.LSEState = RCC_LSE_ON;
  RCC_OscInitStruct.PLL.PLLState = RCC_PLL_ON;
  RCC_OscInitStruct.PLL.PLLSource = RCC_PLLSOURCE_HSE;
  RCC_OscInitStruct.PLL.PLLM = 26;
  RCC_OscInitStruct.PLL.PLLN = 336;
  RCC_OscInitStruct.PLL.PLLP = RCC_PLLP_DIV2;
  RCC_OscInitStruct.PLL.PLLQ = 4;
  if (HAL_RCC_OscConfig(&RCC_OscInitStruct) != HAL_OK)
  {
    _Error_Handler(__FILE__, __LINE__);
  }

    /**Initializes the CPU, AHB and APB busses clocks
    */
  RCC_ClkInitStruct.ClockType = RCC_CLOCKTYPE_HCLK|RCC_CLOCKTYPE_SYSCLK
                              |RCC_CLOCKTYPE_PCLK1|RCC_CLOCKTYPE_PCLK2;
  RCC_ClkInitStruct.SYSCLKSource = RCC_SYSCLKSOURCE_PLLCLK;
  RCC_ClkInitStruct.AHBCLKDivider = RCC_SYSCLK_DIV1;
  RCC_ClkInitStruct.APB1CLKDivider = RCC_HCLK_DIV4;
  RCC_ClkInitStruct.APB2CLKDivider = RCC_HCLK_DIV2;

  if (HAL_RCC_ClockConfig(&RCC_ClkInitStruct, FLASH_LATENCY_5) != HAL_OK)
  {
    _Error_Handler(__FILE__, __LINE__);
  }

  PeriphClkInitStruct.PeriphClockSelection = RCC_PERIPHCLK_RTC;
  PeriphClkInitStruct.RTCClockSelection = RCC_RTCCLKSOURCE_LSE;
  if (HAL_RCCEx_PeriphCLKConfig(&PeriphClkInitStruct) != HAL_OK)
  {
    _Error_Handler(__FILE__, __LINE__);
  }

    /**Configure the Systick interrupt time
    */
  HAL_SYSTICK_Config(HAL_RCC_GetHCLKFreq()/1000);

    /**Configure the Systick
    */
  HAL_SYSTICK_CLKSourceConfig(SYSTICK_CLKSOURCE_HCLK);

  /* SysTick_IRQn interrupt configuration */
  HAL_NVIC_SetPriority(SysTick_IRQn, 0, 0);
}

/* ADC1 init function */
static void MX_ADC1_Init(void)
{

  ADC_ChannelConfTypeDef sConfig;

    /**Configure the global features of the ADC (Clock, Resolution, Data Alignment and number of conversion)
    */
  hadc1.Instance = ADC1;
  hadc1.Init.ClockPrescaler = ADC_CLOCK_SYNC_PCLK_DIV4;
  hadc1.Init.Resolution = ADC_RESOLUTION_12B;
  hadc1.Init.ScanConvMode = ENABLE;
  hadc1.Init.ContinuousConvMode = DISABLE;
  hadc1.Init.DiscontinuousConvMode = DISABLE;
  hadc1.Init.ExternalTrigConvEdge = ADC_EXTERNALTRIGCONVEDGE_NONE;
  hadc1.Init.ExternalTrigConv = ADC_SOFTWARE_START;
  hadc1.Init.DataAlign = ADC_DATAALIGN_RIGHT;
  hadc1.Init.NbrOfConversion = 10;
  hadc1.Init.DMAContinuousRequests = DISABLE;
  hadc1.Init.EOCSelection = ADC_EOC_SINGLE_CONV;
  if (HAL_ADC_Init(&hadc1) != HAL_OK)
  {
    _Error_Handler(__FILE__, __LINE__);
  }

    /**Configure for the selected ADC regular channel its corresponding rank in the sequencer and its sample time.
    */
  sConfig.Channel = ADC_CHANNEL_2;
  sConfig.Rank = 1;
  sConfig.SamplingTime = ADC_SAMPLETIME_3CYCLES;
  if (HAL_ADC_ConfigChannel(&hadc1, &sConfig) != HAL_OK)
  {
    _Error_Handler(__FILE__, __LINE__);
  }

    /**Configure for the selected ADC regular channel its corresponding rank in the sequencer and its sample time.
    */
  sConfig.Rank = 2;
  if (HAL_ADC_ConfigChannel(&hadc1, &sConfig) != HAL_OK)
  {
    _Error_Handler(__FILE__, __LINE__);
  }

    /**Configure for the selected ADC regular channel its corresponding rank in the sequencer and its sample time.
    */
  sConfig.Rank = 3;
  if (HAL_ADC_ConfigChannel(&hadc1, &sConfig) != HAL_OK)
  {
    _Error_Handler(__FILE__, __LINE__);
  }

    /**Configure for the selected ADC regular channel its corresponding rank in the sequencer and its sample time.
    */
  sConfig.Rank = 4;
  if (HAL_ADC_ConfigChannel(&hadc1, &sConfig) != HAL_OK)
  {
    _Error_Handler(__FILE__, __LINE__);
  }

    /**Configure for the selected ADC regular channel its corresponding rank in the sequencer and its sample time.
    */
  sConfig.Rank = 5;
  if (HAL_ADC_ConfigChannel(&hadc1, &sConfig) != HAL_OK)
  {
    _Error_Handler(__FILE__, __LINE__);
  }

    /**Configure for the selected ADC regular channel its corresponding rank in the sequencer and its sample time.
    */
  sConfig.Rank = 6;
  if (HAL_ADC_ConfigChannel(&hadc1, &sConfig) != HAL_OK)
  {
    _Error_Handler(__FILE__, __LINE__);
  }

    /**Configure for the selected ADC regular channel its corresponding rank in the sequencer and its sample time.
    */
  sConfig.Rank = 7;
  if (HAL_ADC_ConfigChannel(&hadc1, &sConfig) != HAL_OK)
  {
    _Error_Handler(__FILE__, __LINE__);
  }

    /**Configure for the selected ADC regular channel its corresponding rank in the sequencer and its sample time.
    */
  sConfig.Rank = 8;
  if (HAL_ADC_ConfigChannel(&hadc1, &sConfig) != HAL_OK)
  {
    _Error_Handler(__FILE__, __LINE__);
  }

    /**Configure for the selected ADC regular channel its corresponding rank in the sequencer and its sample time.
    */
  sConfig.Rank = 9;
  if (HAL_ADC_ConfigChannel(&hadc1, &sConfig) != HAL_OK)
  {
    _Error_Handler(__FILE__, __LINE__);
  }

    /**Configure for the selected ADC regular channel its corresponding rank in the sequencer and its sample time.
    */
  sConfig.Rank = 10;
  if (HAL_ADC_ConfigChannel(&hadc1, &sConfig) != HAL_OK)
  {
    _Error_Handler(__FILE__, __LINE__);
  }

}

/* CRC init function */
static void MX_CRC_Init(void)
{

  hcrc.Instance = CRC;
  if (HAL_CRC_Init(&hcrc) != HAL_OK)
  {
    _Error_Handler(__FILE__, __LINE__);
  }

}

/* I2C1 init function */
static void MX_I2C1_Init(void)
{

  hi2c1.Instance = I2C1;
  hi2c1.Init.ClockSpeed = 400000;
  hi2c1.Init.DutyCycle = I2C_DUTYCYCLE_2;
  hi2c1.Init.OwnAddress1 = 0;
  hi2c1.Init.AddressingMode = I2C_ADDRESSINGMODE_7BIT;
  hi2c1.Init.DualAddressMode = I2C_DUALADDRESS_DISABLE;
  hi2c1.Init.OwnAddress2 = 0;
  hi2c1.Init.GeneralCallMode = I2C_GENERALCALL_DISABLE;
  hi2c1.Init.NoStretchMode = I2C_NOSTRETCH_DISABLE;
  if (HAL_I2C_Init(&hi2c1) != HAL_OK)
  {
    _Error_Handler(__FILE__, __LINE__);
  }

}

/* RTC init function */
static void MX_RTC_Init(void)
{

  RTC_TimeTypeDef sTime;
  RTC_DateTypeDef sDate;

    /**Initialize RTC Only
    */
  hrtc.Instance = RTC;
  hrtc.Init.HourFormat = RTC_HOURFORMAT_24;
  hrtc.Init.AsynchPrediv = 127;
  hrtc.Init.SynchPrediv = 255;
  hrtc.Init.OutPut = RTC_OUTPUT_DISABLE;
  hrtc.Init.OutPutPolarity = RTC_OUTPUT_POLARITY_HIGH;
  hrtc.Init.OutPutType = RTC_OUTPUT_TYPE_OPENDRAIN;
  if (HAL_RTC_Init(&hrtc) != HAL_OK)
  {
    _Error_Handler(__FILE__, __LINE__);
  }

    /**Initialize RTC and set the Time and Date
    */
  if(HAL_RTCEx_BKUPRead(&hrtc, RTC_BKP_DR0) != 0x32F2){
  sTime.Hours = 0;
  sTime.Minutes = 0;
  sTime.Seconds = 0;
  sTime.DayLightSaving = RTC_DAYLIGHTSAVING_NONE;
  sTime.StoreOperation = RTC_STOREOPERATION_RESET;
  if (HAL_RTC_SetTime(&hrtc, &sTime, RTC_FORMAT_BIN) != HAL_OK)
  {
    _Error_Handler(__FILE__, __LINE__);
  }

  sDate.WeekDay = RTC_WEEKDAY_MONDAY;
  sDate.Month = RTC_MONTH_JANUARY;
  sDate.Date = 1;
  sDate.Year = 0;

  if (HAL_RTC_SetDate(&hrtc, &sDate, RTC_FORMAT_BIN) != HAL_OK)
  {
    _Error_Handler(__FILE__, __LINE__);
  }

    HAL_RTCEx_BKUPWrite(&hrtc,RTC_BKP_DR0,0x32F2);
  }

}

/* SPI1 init function */
static void MX_SPI1_Init(void)
{

  hspi1.Instance = SPI1;
  hspi1.Init.Mode = SPI_MODE_MASTER;
  hspi1.Init.Direction = SPI_DIRECTION_2LINES;
  hspi1.Init.DataSize = SPI_DATASIZE_8BIT;
  hspi1.Init.CLKPolarity = SPI_POLARITY_LOW;
  hspi1.Init.CLKPhase = SPI_PHASE_1EDGE;
  hspi1.Init.NSS = SPI_NSS_SOFT;
  hspi1.Init.BaudRatePrescaler = SPI_BAUDRATEPRESCALER_8;
  hspi1.Init.FirstBit = SPI_FIRSTBIT_MSB;
  hspi1.Init.TIMode = SPI_TIMODE_DISABLE;
  hspi1.Init.CRCCalculation = SPI_CRCCALCULATION_DISABLE;
  hspi1.Init.CRCPolynomial = 10;
  if (HAL_SPI_Init(&hspi1) != HAL_OK)
  {
    _Error_Handler(__FILE__, __LINE__);
  }

}

/* SPI3 init function */
static void MX_SPI3_Init(void)
{

  hspi3.Instance = SPI3;
  hspi3.Init.Mode = SPI_MODE_MASTER;
  hspi3.Init.Direction = SPI_DIRECTION_2LINES;
  hspi3.Init.DataSize = SPI_DATASIZE_8BIT;
  hspi3.Init.CLKPolarity = SPI_POLARITY_LOW;
  hspi3.Init.CLKPhase = SPI_PHASE_1EDGE;
  hspi3.Init.NSS = SPI_NSS_SOFT;
  hspi3.Init.BaudRatePrescaler = SPI_BAUDRATEPRESCALER_4;
  hspi3.Init.FirstBit = SPI_FIRSTBIT_MSB;
  hspi3.Init.TIMode = SPI_TIMODE_DISABLE;
  hspi3.Init.CRCCalculation = SPI_CRCCALCULATION_DISABLE;
  hspi3.Init.CRCPolynomial = 10;
  if (HAL_SPI_Init(&hspi3) != HAL_OK)
  {
    _Error_Handler(__FILE__, __LINE__);
  }

}

/* SPI4 init function */
static void MX_SPI4_Init(void)
{

  hspi4.Instance = SPI4;
  hspi4.Init.Mode = SPI_MODE_MASTER;
  hspi4.Init.Direction = SPI_DIRECTION_2LINES;
  hspi4.Init.DataSize = SPI_DATASIZE_8BIT;
  hspi4.Init.CLKPolarity = SPI_POLARITY_LOW;
  hspi4.Init.CLKPhase = SPI_PHASE_1EDGE;
  hspi4.Init.NSS = SPI_NSS_SOFT;
  hspi4.Init.BaudRatePrescaler = SPI_BAUDRATEPRESCALER_8;
  hspi4.Init.FirstBit = SPI_FIRSTBIT_MSB;
  hspi4.Init.TIMode = SPI_TIMODE_DISABLE;
  hspi4.Init.CRCCalculation = SPI_CRCCALCULATION_DISABLE;
  hspi4.Init.CRCPolynomial = 10;
  if (HAL_SPI_Init(&hspi4) != HAL_OK)
  {
    _Error_Handler(__FILE__, __LINE__);
  }

}

/* SPI5 init function */
static void MX_SPI5_Init(void)
{

  hspi5.Instance = SPI5;
  hspi5.Init.Mode = SPI_MODE_MASTER;
  hspi5.Init.Direction = SPI_DIRECTION_2LINES;
  hspi5.Init.DataSize = SPI_DATASIZE_8BIT;
  hspi5.Init.CLKPolarity = SPI_POLARITY_LOW;
  hspi5.Init.CLKPhase = SPI_PHASE_1EDGE;
  hspi5.Init.NSS = SPI_NSS_SOFT;
  hspi5.Init.BaudRatePrescaler = SPI_BAUDRATEPRESCALER_8;
  hspi5.Init.FirstBit = SPI_FIRSTBIT_MSB;
  hspi5.Init.TIMode = SPI_TIMODE_DISABLE;
  hspi5.Init.CRCCalculation = SPI_CRCCALCULATION_DISABLE;
  hspi5.Init.CRCPolynomial = 10;
  if (HAL_SPI_Init(&hspi5) != HAL_OK)
  {
    _Error_Handler(__FILE__, __LINE__);
  }

}

/* TIM2 init function */
static void MX_TIM2_Init(void)
{

  TIM_ClockConfigTypeDef sClockSourceConfig;
  TIM_MasterConfigTypeDef sMasterConfig;

  htim2.Instance = TIM2;
  htim2.Init.Prescaler = 168;
  htim2.Init.CounterMode = TIM_COUNTERMODE_UP;
  htim2.Init.Period = 800000;
  htim2.Init.ClockDivision = TIM_CLOCKDIVISION_DIV1;
  if (HAL_TIM_Base_Init(&htim2) != HAL_OK)
  {
    _Error_Handler(__FILE__, __LINE__);
  }

  sClockSourceConfig.ClockSource = TIM_CLOCKSOURCE_INTERNAL;
  if (HAL_TIM_ConfigClockSource(&htim2, &sClockSourceConfig) != HAL_OK)
  {
    _Error_Handler(__FILE__, __LINE__);
  }

  sMasterConfig.MasterOutputTrigger = TIM_TRGO_RESET;
  sMasterConfig.MasterSlaveMode = TIM_MASTERSLAVEMODE_DISABLE;
  if (HAL_TIMEx_MasterConfigSynchronization(&htim2, &sMasterConfig) != HAL_OK)
  {
    _Error_Handler(__FILE__, __LINE__);
  }

}

/* USART2 init function */
static void MX_USART2_UART_Init(void)
{

  huart2.Instance = USART2;
  huart2.Init.BaudRate = 115200;
  huart2.Init.WordLength = UART_WORDLENGTH_8B;
  huart2.Init.StopBits = UART_STOPBITS_1;
  huart2.Init.Parity = UART_PARITY_NONE;
  huart2.Init.Mode = UART_MODE_TX_RX;
  huart2.Init.HwFlowCtl = UART_HWCONTROL_NONE;
  huart2.Init.OverSampling = UART_OVERSAMPLING_16;
  if (HAL_UART_Init(&huart2) != HAL_OK)
  {
    _Error_Handler(__FILE__, __LINE__);
  }

}

/* USART3 init function */
static void MX_USART3_UART_Init(void)
{

  huart3.Instance = USART3;
  huart3.Init.BaudRate = 460800;
  huart3.Init.WordLength = UART_WORDLENGTH_8B;
  huart3.Init.StopBits = UART_STOPBITS_1;
  huart3.Init.Parity = UART_PARITY_NONE;
  huart3.Init.Mode = UART_MODE_TX_RX;
  huart3.Init.HwFlowCtl = UART_HWCONTROL_NONE;
  huart3.Init.OverSampling = UART_OVERSAMPLING_16;
  if (HAL_UART_Init(&huart3) != HAL_OK)
  {
    _Error_Handler(__FILE__, __LINE__);
  }

}

/* USART6 init function */
static void MX_USART6_UART_Init(void)
{

  huart6.Instance = USART6;
  huart6.Init.BaudRate = 115200;
  huart6.Init.WordLength = UART_WORDLENGTH_8B;
  huart6.Init.StopBits = UART_STOPBITS_1;
  huart6.Init.Parity = UART_PARITY_NONE;
  huart6.Init.Mode = UART_MODE_TX_RX;
  huart6.Init.HwFlowCtl = UART_HWCONTROL_NONE;
  huart6.Init.OverSampling = UART_OVERSAMPLING_16;
  if (HAL_UART_Init(&huart6) != HAL_OK)
  {
    _Error_Handler(__FILE__, __LINE__);
  }

}

static void MX_DMA_Init(void)
{
  /* DMA controller clock enable */
  __HAL_RCC_DMA1_CLK_ENABLE();
  __HAL_RCC_DMA2_CLK_ENABLE();

  /* DMA interrupt init */
  /* DMA1_Stream0_IRQn interrupt configuration */
  HAL_NVIC_SetPriority(DMA1_Stream0_IRQn, 0, 0);
  HAL_NVIC_EnableIRQ(DMA1_Stream0_IRQn);
  /* DMA1_Stream1_IRQn interrupt configuration */
  HAL_NVIC_SetPriority(DMA1_Stream1_IRQn, 2, 0);
  HAL_NVIC_EnableIRQ(DMA1_Stream1_IRQn);
  /* DMA1_Stream2_IRQn interrupt configuration */
  HAL_NVIC_SetPriority(DMA1_Stream2_IRQn, 1, 0);
  HAL_NVIC_EnableIRQ(DMA1_Stream2_IRQn);
  /* DMA1_Stream3_IRQn interrupt configuration */
  HAL_NVIC_SetPriority(DMA1_Stream3_IRQn, 2, 0);
  HAL_NVIC_EnableIRQ(DMA1_Stream3_IRQn);
  /* DMA1_Stream5_IRQn interrupt configuration */
  HAL_NVIC_SetPriority(DMA1_Stream5_IRQn, 2, 0);
  HAL_NVIC_EnableIRQ(DMA1_Stream5_IRQn);
  /* DMA1_Stream6_IRQn interrupt configuration */
  HAL_NVIC_SetPriority(DMA1_Stream6_IRQn, 2, 0);
  HAL_NVIC_EnableIRQ(DMA1_Stream6_IRQn);
  /* DMA1_Stream7_IRQn interrupt configuration */
  HAL_NVIC_SetPriority(DMA1_Stream7_IRQn, 0, 0);
  HAL_NVIC_EnableIRQ(DMA1_Stream7_IRQn);
  /* DMA2_Stream0_IRQn interrupt configuration */
  HAL_NVIC_SetPriority(DMA2_Stream0_IRQn, 1, 0);
  HAL_NVIC_EnableIRQ(DMA2_Stream0_IRQn);
  /* DMA2_Stream1_IRQn interrupt configuration */
  HAL_NVIC_SetPriority(DMA2_Stream1_IRQn, 2, 0);
  HAL_NVIC_EnableIRQ(DMA2_Stream1_IRQn);
  /* DMA2_Stream2_IRQn interrupt configuration */
  HAL_NVIC_SetPriority(DMA2_Stream2_IRQn, 1, 0);
  HAL_NVIC_EnableIRQ(DMA2_Stream2_IRQn);
  /* DMA2_Stream3_IRQn interrupt configuration */
  HAL_NVIC_SetPriority(DMA2_Stream3_IRQn, 1, 0);
  HAL_NVIC_EnableIRQ(DMA2_Stream3_IRQn);
  /* DMA2_Stream6_IRQn interrupt configuration */
  HAL_NVIC_SetPriority(DMA2_Stream6_IRQn, 2, 0);
  HAL_NVIC_EnableIRQ(DMA2_Stream6_IRQn);

}

/** Configure pins as
        * Analog
        * Input
        * Output
        * EVENT_OUT
        * EXTI
        * Free pins are configured automatically as Analog (this feature is enabled through
        * the Code Generation settings)
*/
static void MX_GPIO_Init(void)
{

  GPIO_InitTypeDef GPIO_InitStruct;

  /* GPIO Ports Clock Enable */
  __HAL_RCC_GPIOE_CLK_ENABLE();
  __HAL_RCC_GPIOI_CLK_ENABLE();
  __HAL_RCC_GPIOC_CLK_ENABLE();
  __HAL_RCC_GPIOF_CLK_ENABLE();
  __HAL_RCC_GPIOH_CLK_ENABLE();
  __HAL_RCC_GPIOA_CLK_ENABLE();
  __HAL_RCC_GPIOB_CLK_ENABLE();
  __HAL_RCC_GPIOG_CLK_ENABLE();
  __HAL_RCC_GPIOD_CLK_ENABLE();

  /*Configure GPIO pin Output Level */
  HAL_GPIO_WritePin(SPI3_rf_power_onoff_GPIO_Port, SPI3_rf_power_onoff_Pin, GPIO_PIN_RESET);

  /*Configure GPIO pin Output Level */
  HAL_GPIO_WritePin(GPIOF, SPI5_rf_io_reset_Pin|SPI5_rf_io_vreg_Pin|SPI5_rf_tx_Pin|SPI5_rf_rfoff_Pin
                          |SPI5_rf_io_fifo_Pin|SPI5_rf_cs_Pin|SPI1_rf_io_fifo_Pin, GPIO_PIN_SET);

  /*Configure GPIO pin Output Level */
  HAL_GPIO_WritePin(GPIOF, SPI5_rf_power_onoff_Pin|SPI1_rf_power_onoff_Pin, GPIO_PIN_RESET);

  /*Configure GPIO pin Output Level */
  HAL_GPIO_WritePin(GPIOH, adc_enable_Pin|SPI4_rf_tx_Pin|SPI4_rf_rfoff_Pin|SPI3_rf_io_reset_Pin, GPIO_PIN_SET);

  /*Configure GPIO pin Output Level */
  HAL_GPIO_WritePin(GPIOA, SPI1_rf_cs_Pin|SPI3_rf_cs_Pin, GPIO_PIN_SET);

  /*Configure GPIO pin Output Level */
  HAL_GPIO_WritePin(GPIOC, SPI1_rf_io_vreg_Pin|SPI1_rf_io_reset_Pin, GPIO_PIN_SET);

  /*Configure GPIO pin Output Level */
  HAL_GPIO_WritePin(GPIOB, SPI1_rf_tx_Pin|SPI1_rf_rfoff_Pin|SPI4_rf_io_fifo_Pin|G4_33TO18_ENABLE_Pin
                          |G4_on_off_Pin|G4_reset_Pin|G4_power_onoff_Pin, GPIO_PIN_SET);

  /*Configure GPIO pin Output Level */
  HAL_GPIO_WritePin(GPIOE, Watch_dog_io_Pin|SPI4_rf_cs_Pin, GPIO_PIN_SET);

  /*Configure GPIO pin Output Level */
  HAL_GPIO_WritePin(SPI4_rf_io_vreg_GPIO_Port, SPI4_rf_io_vreg_Pin, GPIO_PIN_RESET);

  /*Configure GPIO pin Output Level */
  HAL_GPIO_WritePin(GPIOH, SPI4_rf_io_reset_Pin|SPI4_rf_power_onoff_Pin|SPI3_rf_io_vreg_Pin, GPIO_PIN_RESET);

  /*Configure GPIO pin Output Level */
  HAL_GPIO_WritePin(GPIOD, GPRS_pwoer_onoff_Pin|SPI4_led_crc_error_Pin, GPIO_PIN_RESET);

  /*Configure GPIO pin Output Level */
  HAL_GPIO_WritePin(GPIOG, general_led_1_Pin|general_led_2_Pin|general_led_3_Pin|general_led_4_Pin
                          |general_led_5_Pin|SPI1_led_crc_error_Pin|SPI1_led_rf_send_Pin|SPI5_led_crc_error_Pin
                          |SPI5_led_rf_send_Pin, GPIO_PIN_RESET);

  /*Configure GPIO pin Output Level */
  HAL_GPIO_WritePin(general_led_6_GPIO_Port, general_led_6_Pin, GPIO_PIN_SET);

  /*Configure GPIO pin Output Level */
  HAL_GPIO_WritePin(GPIOI, SPI3_rf_tx_Pin|SPI3_rf_rfoff_Pin|SPI3_rf_io_fifo_Pin, GPIO_PIN_SET);

  /*Configure GPIO pin Output Level */
  HAL_GPIO_WritePin(GPRS_powerkey_GPIO_Port, GPRS_powerkey_Pin, GPIO_PIN_SET);

  /*Configure GPIO pin Output Level */
  HAL_GPIO_WritePin(GPIOI, SPI3_led_crc_error_Pin|SPI3_led_rf_send_Pin, GPIO_PIN_RESET);

  /*Configure GPIO pins : PE2 PE3 PE4 PE5
                           PE6 PE7 PE8 PE10
                           PE0 PE1 */
  GPIO_InitStruct.Pin = GPIO_PIN_2|GPIO_PIN_3|GPIO_PIN_4|GPIO_PIN_5
                          |GPIO_PIN_6|GPIO_PIN_7|GPIO_PIN_8|GPIO_PIN_10
                          |GPIO_PIN_0|GPIO_PIN_1;
  GPIO_InitStruct.Mode = GPIO_MODE_ANALOG;
  GPIO_InitStruct.Pull = GPIO_NOPULL;
  HAL_GPIO_Init(GPIOE, &GPIO_InitStruct);

  /*Configure GPIO pins : PI8 PI9 PI10 PI11
                           PI4 PI5 */
  GPIO_InitStruct.Pin = GPIO_PIN_8|GPIO_PIN_9|GPIO_PIN_10|GPIO_PIN_11
                          |GPIO_PIN_4|GPIO_PIN_5;
  GPIO_InitStruct.Mode = GPIO_MODE_ANALOG;
  GPIO_InitStruct.Pull = GPIO_NOPULL;
  HAL_GPIO_Init(GPIOI, &GPIO_InitStruct);

  /*Configure GPIO pin : SPI3_rf_power_onoff_Pin */
  GPIO_InitStruct.Pin = SPI3_rf_power_onoff_Pin;
  GPIO_InitStruct.Mode = GPIO_MODE_OUTPUT_PP;
  GPIO_InitStruct.Pull = GPIO_PULLUP;
  GPIO_InitStruct.Speed = GPIO_SPEED_FREQ_LOW;
  HAL_GPIO_Init(SPI3_rf_power_onoff_GPIO_Port, &GPIO_InitStruct);

  /*Configure GPIO pins : SPI5_rf_io_reset_Pin SPI5_rf_io_vreg_Pin SPI5_rf_tx_Pin SPI5_rf_rfoff_Pin
                           SPI5_rf_io_fifo_Pin SPI5_rf_cs_Pin SPI1_rf_io_fifo_Pin */
  GPIO_InitStruct.Pin = SPI5_rf_io_reset_Pin|SPI5_rf_io_vreg_Pin|SPI5_rf_tx_Pin|SPI5_rf_rfoff_Pin
                          |SPI5_rf_io_fifo_Pin|SPI5_rf_cs_Pin|SPI1_rf_io_fifo_Pin;
  GPIO_InitStruct.Mode = GPIO_MODE_OUTPUT_PP;
  GPIO_InitStruct.Pull = GPIO_PULLUP;
  GPIO_InitStruct.Speed = GPIO_SPEED_FREQ_VERY_HIGH;
  HAL_GPIO_Init(GPIOF, &GPIO_InitStruct);

  /*Configure GPIO pins : SPI5_rf_io_fifop_Pin SPI1_rf_io_fifop_Pin */
  GPIO_InitStruct.Pin = SPI5_rf_io_fifop_Pin|SPI1_rf_io_fifop_Pin;
  GPIO_InitStruct.Mode = GPIO_MODE_IT_RISING;
  GPIO_InitStruct.Pull = GPIO_NOPULL;
  HAL_GPIO_Init(GPIOF, &GPIO_InitStruct);

  /*Configure GPIO pins : SPI5_rf_power_onoff_Pin SPI1_rf_power_onoff_Pin */
  GPIO_InitStruct.Pin = SPI5_rf_power_onoff_Pin|SPI1_rf_power_onoff_Pin;
  GPIO_InitStruct.Mode = GPIO_MODE_OUTPUT_PP;
  GPIO_InitStruct.Pull = GPIO_PULLUP;
  GPIO_InitStruct.Speed = GPIO_SPEED_FREQ_LOW;
  HAL_GPIO_Init(GPIOF, &GPIO_InitStruct);

  /*Configure GPIO pins : PC0 PC1 PC2 PC3
                           PC6 PC7 PC8 PC9 */
  GPIO_InitStruct.Pin = GPIO_PIN_0|GPIO_PIN_1|GPIO_PIN_2|GPIO_PIN_3
                          |GPIO_PIN_6|GPIO_PIN_7|GPIO_PIN_8|GPIO_PIN_9;
  GPIO_InitStruct.Mode = GPIO_MODE_ANALOG;
  GPIO_InitStruct.Pull = GPIO_NOPULL;
  HAL_GPIO_Init(GPIOC, &GPIO_InitStruct);

  /*Configure GPIO pins : PA0 PA1 PA3 PA8
                           PA9 PA10 PA11 PA12 */
  GPIO_InitStruct.Pin = GPIO_PIN_0|GPIO_PIN_1|GPIO_PIN_3|GPIO_PIN_8
                          |GPIO_PIN_9|GPIO_PIN_10|GPIO_PIN_11|GPIO_PIN_12;
  GPIO_InitStruct.Mode = GPIO_MODE_ANALOG;
  GPIO_InitStruct.Pull = GPIO_NOPULL;
  HAL_GPIO_Init(GPIOA, &GPIO_InitStruct);

  /*Configure GPIO pin : adc_enable_Pin */
  GPIO_InitStruct.Pin = adc_enable_Pin;
  GPIO_InitStruct.Mode = GPIO_MODE_OUTPUT_PP;
  GPIO_InitStruct.Pull = GPIO_NOPULL;
  GPIO_InitStruct.Speed = GPIO_SPEED_FREQ_HIGH;
  HAL_GPIO_Init(adc_enable_GPIO_Port, &GPIO_InitStruct);

  /*Configure GPIO pins : PH3 PH4 PH5 PH10
                           PH11 PH12 PH15 */
  GPIO_InitStruct.Pin = GPIO_PIN_3|GPIO_PIN_4|GPIO_PIN_5|GPIO_PIN_10
                          |GPIO_PIN_11|GPIO_PIN_12|GPIO_PIN_15;
  GPIO_InitStruct.Mode = GPIO_MODE_ANALOG;
  GPIO_InitStruct.Pull = GPIO_NOPULL;
  HAL_GPIO_Init(GPIOH, &GPIO_InitStruct);

  /*Configure GPIO pins : SPI1_rf_cs_Pin SPI3_rf_cs_Pin */
  GPIO_InitStruct.Pin = SPI1_rf_cs_Pin|SPI3_rf_cs_Pin;
  GPIO_InitStruct.Mode = GPIO_MODE_OUTPUT_PP;
  GPIO_InitStruct.Pull = GPIO_PULLUP;
  GPIO_InitStruct.Speed = GPIO_SPEED_FREQ_VERY_HIGH;
  HAL_GPIO_Init(GPIOA, &GPIO_InitStruct);

  /*Configure GPIO pins : SPI1_rf_io_vreg_Pin SPI1_rf_io_reset_Pin */
  GPIO_InitStruct.Pin = SPI1_rf_io_vreg_Pin|SPI1_rf_io_reset_Pin;
  GPIO_InitStruct.Mode = GPIO_MODE_OUTPUT_PP;
  GPIO_InitStruct.Pull = GPIO_PULLUP;
  GPIO_InitStruct.Speed = GPIO_SPEED_FREQ_VERY_HIGH;
  HAL_GPIO_Init(GPIOC, &GPIO_InitStruct);

  /*Configure GPIO pins : SPI1_rf_tx_Pin SPI1_rf_rfoff_Pin SPI4_rf_io_fifo_Pin */
  GPIO_InitStruct.Pin = SPI1_rf_tx_Pin|SPI1_rf_rfoff_Pin|SPI4_rf_io_fifo_Pin;
  GPIO_InitStruct.Mode = GPIO_MODE_OUTPUT_PP;
  GPIO_InitStruct.Pull = GPIO_PULLUP;
  GPIO_InitStruct.Speed = GPIO_SPEED_FREQ_VERY_HIGH;
  HAL_GPIO_Init(GPIOB, &GPIO_InitStruct);

  /*Configure GPIO pins : PB2 PB12 PB13 PB14
                           PB5 PB9 */
  GPIO_InitStruct.Pin = GPIO_PIN_2|GPIO_PIN_12|GPIO_PIN_13|GPIO_PIN_14
                          |GPIO_PIN_5|GPIO_PIN_9;
  GPIO_InitStruct.Mode = GPIO_MODE_ANALOG;
  GPIO_InitStruct.Pull = GPIO_NOPULL;
  HAL_GPIO_Init(GPIOB, &GPIO_InitStruct);

  /*Configure GPIO pins : PF14 PF15 */
  GPIO_InitStruct.Pin = GPIO_PIN_14|GPIO_PIN_15;
  GPIO_InitStruct.Mode = GPIO_MODE_ANALOG;
  GPIO_InitStruct.Pull = GPIO_NOPULL;
  HAL_GPIO_Init(GPIOF, &GPIO_InitStruct);

  /*Configure GPIO pins : PG0 PG1 PG8 PG15 */
  GPIO_InitStruct.Pin = GPIO_PIN_0|GPIO_PIN_1|GPIO_PIN_8|GPIO_PIN_15;
  GPIO_InitStruct.Mode = GPIO_MODE_ANALOG;
  GPIO_InitStruct.Pull = GPIO_NOPULL;
  HAL_GPIO_Init(GPIOG, &GPIO_InitStruct);

  /*Configure GPIO pins : Watch_dog_io_Pin SPI4_rf_cs_Pin */
  GPIO_InitStruct.Pin = Watch_dog_io_Pin|SPI4_rf_cs_Pin;
  GPIO_InitStruct.Mode = GPIO_MODE_OUTPUT_PP;
  GPIO_InitStruct.Pull = GPIO_PULLUP;
  GPIO_InitStruct.Speed = GPIO_SPEED_FREQ_VERY_HIGH;
  HAL_GPIO_Init(GPIOE, &GPIO_InitStruct);

  /*Configure GPIO pin : SPI4_rf_io_vreg_Pin */
  GPIO_InitStruct.Pin = SPI4_rf_io_vreg_Pin;
  GPIO_InitStruct.Mode = GPIO_MODE_OUTPUT_PP;
  GPIO_InitStruct.Pull = GPIO_PULLUP;
  GPIO_InitStruct.Speed = GPIO_SPEED_FREQ_LOW;
  HAL_GPIO_Init(SPI4_rf_io_vreg_GPIO_Port, &GPIO_InitStruct);

  /*Configure GPIO pin : SPI4_rf_io_fifop_Pin */
  GPIO_InitStruct.Pin = SPI4_rf_io_fifop_Pin;
  GPIO_InitStruct.Mode = GPIO_MODE_IT_RISING;
  GPIO_InitStruct.Pull = GPIO_NOPULL;
  HAL_GPIO_Init(SPI4_rf_io_fifop_GPIO_Port, &GPIO_InitStruct);

  /*Configure GPIO pins : SPI4_rf_io_reset_Pin SPI4_rf_power_onoff_Pin SPI3_rf_io_vreg_Pin */
  GPIO_InitStruct.Pin = SPI4_rf_io_reset_Pin|SPI4_rf_power_onoff_Pin|SPI3_rf_io_vreg_Pin;
  GPIO_InitStruct.Mode = GPIO_MODE_OUTPUT_PP;
  GPIO_InitStruct.Pull = GPIO_PULLUP;
  GPIO_InitStruct.Speed = GPIO_SPEED_FREQ_LOW;
  HAL_GPIO_Init(GPIOH, &GPIO_InitStruct);

  /*Configure GPIO pins : SPI4_rf_tx_Pin SPI4_rf_rfoff_Pin */
  GPIO_InitStruct.Pin = SPI4_rf_tx_Pin|SPI4_rf_rfoff_Pin;
  GPIO_InitStruct.Mode = GPIO_MODE_OUTPUT_PP;
  GPIO_InitStruct.Pull = GPIO_PULLUP;
  GPIO_InitStruct.Speed = GPIO_SPEED_FREQ_VERY_HIGH;
  HAL_GPIO_Init(GPIOH, &GPIO_InitStruct);

  /*Configure GPIO pin : G4_33TO18_ENABLE_Pin */
  GPIO_InitStruct.Pin = G4_33TO18_ENABLE_Pin;
  GPIO_InitStruct.Mode = GPIO_MODE_OUTPUT_OD;
  GPIO_InitStruct.Pull = GPIO_PULLUP;
  GPIO_InitStruct.Speed = GPIO_SPEED_FREQ_HIGH;
  HAL_GPIO_Init(G4_33TO18_ENABLE_GPIO_Port, &GPIO_InitStruct);

  /*Configure GPIO pin : GPRS_pwoer_onoff_Pin */
  GPIO_InitStruct.Pin = GPRS_pwoer_onoff_Pin;
  GPIO_InitStruct.Mode = GPIO_MODE_OUTPUT_PP;
  GPIO_InitStruct.Pull = GPIO_PULLUP;
  GPIO_InitStruct.Speed = GPIO_SPEED_FREQ_LOW;
  HAL_GPIO_Init(GPRS_pwoer_onoff_GPIO_Port, &GPIO_InitStruct);

  /*Configure GPIO pins : PD11 PD12 PD13 PD14
                           PD15 PD0 PD2 PD3
                           PD4 */
  GPIO_InitStruct.Pin = GPIO_PIN_11|GPIO_PIN_12|GPIO_PIN_13|GPIO_PIN_14
                          |GPIO_PIN_15|GPIO_PIN_0|GPIO_PIN_2|GPIO_PIN_3
                          |GPIO_PIN_4;
  GPIO_InitStruct.Mode = GPIO_MODE_ANALOG;
  GPIO_InitStruct.Pull = GPIO_NOPULL;
  HAL_GPIO_Init(GPIOD, &GPIO_InitStruct);

  /*Configure GPIO pins : general_led_1_Pin general_led_2_Pin general_led_3_Pin general_led_4_Pin
                           general_led_5_Pin general_led_6_Pin SPI1_led_crc_error_Pin SPI1_led_rf_send_Pin
                           SPI5_led_crc_error_Pin SPI5_led_rf_send_Pin */
  GPIO_InitStruct.Pin = general_led_1_Pin|general_led_2_Pin|general_led_3_Pin|general_led_4_Pin
                          |general_led_5_Pin|general_led_6_Pin|SPI1_led_crc_error_Pin|SPI1_led_rf_send_Pin
                          |SPI5_led_crc_error_Pin|SPI5_led_rf_send_Pin;
  GPIO_InitStruct.Mode = GPIO_MODE_OUTPUT_OD;
  GPIO_InitStruct.Pull = GPIO_PULLUP;
  GPIO_InitStruct.Speed = GPIO_SPEED_FREQ_LOW;
  HAL_GPIO_Init(GPIOG, &GPIO_InitStruct);

  /*Configure GPIO pin : SPI3_rf_io_reset_Pin */
  GPIO_InitStruct.Pin = SPI3_rf_io_reset_Pin;
  GPIO_InitStruct.Mode = GPIO_MODE_OUTPUT_PP;
  GPIO_InitStruct.Pull = GPIO_PULLUP;
  GPIO_InitStruct.Speed = GPIO_SPEED_FREQ_MEDIUM;
  HAL_GPIO_Init(SPI3_rf_io_reset_GPIO_Port, &GPIO_InitStruct);

  /*Configure GPIO pins : SPI3_rf_tx_Pin SPI3_rf_rfoff_Pin SPI3_rf_io_fifo_Pin */
  GPIO_InitStruct.Pin = SPI3_rf_tx_Pin|SPI3_rf_rfoff_Pin|SPI3_rf_io_fifo_Pin;
  GPIO_InitStruct.Mode = GPIO_MODE_OUTPUT_PP;
  GPIO_InitStruct.Pull = GPIO_PULLUP;
  GPIO_InitStruct.Speed = GPIO_SPEED_FREQ_VERY_HIGH;
  HAL_GPIO_Init(GPIOI, &GPIO_InitStruct);

  /*Configure GPIO pin : SPI3_rf_io_fifop_Pin */
  GPIO_InitStruct.Pin = SPI3_rf_io_fifop_Pin;
  GPIO_InitStruct.Mode = GPIO_MODE_IT_RISING;
  GPIO_InitStruct.Pull = GPIO_NOPULL;
  HAL_GPIO_Init(SPI3_rf_io_fifop_GPIO_Port, &GPIO_InitStruct);

  /*Configure GPIO pin : GPRS_powerkey_Pin */
  GPIO_InitStruct.Pin = GPRS_powerkey_Pin;
  GPIO_InitStruct.Mode = GPIO_MODE_OUTPUT_PP;
  GPIO_InitStruct.Pull = GPIO_PULLDOWN;
  GPIO_InitStruct.Speed = GPIO_SPEED_FREQ_LOW;
  HAL_GPIO_Init(GPRS_powerkey_GPIO_Port, &GPIO_InitStruct);

  /*Configure GPIO pin : SPI4_led_crc_error_Pin */
  GPIO_InitStruct.Pin = SPI4_led_crc_error_Pin;
  GPIO_InitStruct.Mode = GPIO_MODE_OUTPUT_OD;
  GPIO_InitStruct.Pull = GPIO_PULLUP;
  GPIO_InitStruct.Speed = GPIO_SPEED_FREQ_LOW;
  HAL_GPIO_Init(SPI4_led_crc_error_GPIO_Port, &GPIO_InitStruct);

  /*Configure GPIO pins : G4_on_off_Pin G4_power_onoff_Pin */
  GPIO_InitStruct.Pin = G4_on_off_Pin|G4_power_onoff_Pin;
  GPIO_InitStruct.Mode = GPIO_MODE_OUTPUT_PP;
  GPIO_InitStruct.Pull = GPIO_PULLUP;
  GPIO_InitStruct.Speed = GPIO_SPEED_FREQ_MEDIUM;
  HAL_GPIO_Init(GPIOB, &GPIO_InitStruct);

  /*Configure GPIO pin : G4_reset_Pin */
  GPIO_InitStruct.Pin = G4_reset_Pin;
  GPIO_InitStruct.Mode = GPIO_MODE_OUTPUT_PP;
  GPIO_InitStruct.Pull = GPIO_PULLUP;
  GPIO_InitStruct.Speed = GPIO_SPEED_FREQ_HIGH;
  HAL_GPIO_Init(G4_reset_GPIO_Port, &GPIO_InitStruct);

  /*Configure GPIO pins : SPI3_led_crc_error_Pin SPI3_led_rf_send_Pin */
  GPIO_InitStruct.Pin = SPI3_led_crc_error_Pin|SPI3_led_rf_send_Pin;
  GPIO_InitStruct.Mode = GPIO_MODE_OUTPUT_OD;
  GPIO_InitStruct.Pull = GPIO_PULLUP;
  GPIO_InitStruct.Speed = GPIO_SPEED_FREQ_LOW;
  HAL_GPIO_Init(GPIOI, &GPIO_InitStruct);

  /* EXTI interrupt init*/
  HAL_NVIC_SetPriority(EXTI2_IRQn, 2, 0);
  HAL_NVIC_EnableIRQ(EXTI2_IRQn);

  HAL_NVIC_SetPriority(EXTI4_IRQn, 2, 0);
  HAL_NVIC_EnableIRQ(EXTI4_IRQn);

  HAL_NVIC_SetPriority(EXTI15_10_IRQn, 1, 0);
  HAL_NVIC_EnableIRQ(EXTI15_10_IRQn);

}

void _Error_Handler(char * file, int line)
{
  while(1)
  {
  }
}

/************************ (C) COPYRIGHT STMicroelectronics *****END OF FILE****/
